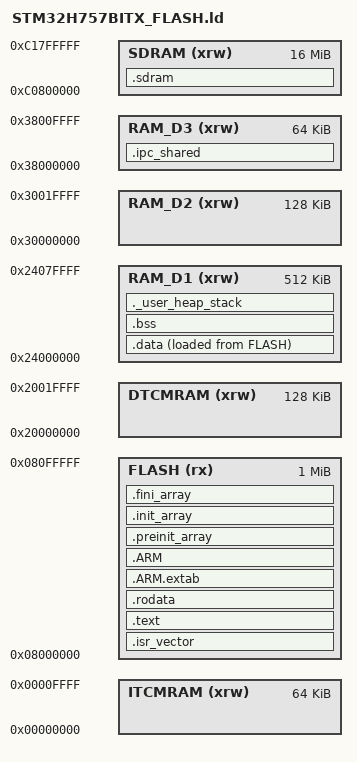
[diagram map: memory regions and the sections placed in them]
/*
******************************************************************************
**
**  File        : LinkerScript.ld
**
**  Author      : STM32CubeIDE
**
**  Abstract    : Linker script for STM32H7 series
**                      1024Kbytes FLASH
**                      800Kbytes RAM
**
**                Set heap size, stack size and stack location according
**                to application requirements.
**
**                Set memory bank area and size if external memory is used.
**
**  Target      : STMicroelectronics STM32
**
**  Distribution: The file is distributed as is without any warranty
**                of any kind.
**
*****************************************************************************
** @attention
**
** Copyright (c) 2024 STMicroelectronics.
** All rights reserved.
**
** This software is licensed under terms that can be found in the LICENSE file
** in the root directory of this software component.
** If no LICENSE file comes with this software, it is provided AS-IS.
**
*****************************************************************************
*/

/* Entry Point */
ENTRY(Reset_Handler)

/* Highest address of the user mode stack */
_estack = ORIGIN(RAM_D1) + LENGTH(RAM_D1); /* end of "RAM_D1" Ram type memory */

_Min_Heap_Size = 0x200; /* required amount of heap  */
_Min_Stack_Size = 0x400; /* required amount of stack */

/* Memories definition */
MEMORY
{
  RAM_D1 (xrw)   : ORIGIN = 0x24000000, LENGTH =  512K
  FLASH   (rx)   : ORIGIN = 0x08000000, LENGTH = 1024K    /* Memory is divided. Actual start is 0x08000000 and actual length is 2048K */
  DTCMRAM (xrw)  : ORIGIN = 0x20000000, LENGTH = 128K
  RAM_D2 (xrw)   : ORIGIN = 0x30000000, LENGTH = 128K  /* D2 SPLIT: CM7 = SRAM1 (128K). CM4 vlastni SRAM2+3 (160K @0x10020000, viz CM4 linker + NAVRH §11.5). Diagnosticky 'ram write/read' (0x30001000, ~78 KB) se vejde do SRAM1. CM7 do RAM_D2 nic nelinkuje. */
  RAM_D3 (xrw)   : ORIGIN = 0x38000000, LENGTH = 64K
  ITCMRAM (xrw)  : ORIGIN = 0x00000000, LENGTH = 64K
  /* Externi SDRAM scratch (FMC). 0xC0800000 = volne nad bignum regionem
   * (viz CLAUDE.md SDRAM mapa: R0 2MB @C0000000, R1 4MB @C0400000). Slouzi pro
   * .sdram sekci (libprim glow + screen caches). Mimo MPU R0/R1 -> default mapa
   * = Device pamet (pristupne, DMA2D-koherentni). */
  SDRAM (xrw)    : ORIGIN = 0xC0800000, LENGTH = 16M
}

/* Sections */
SECTIONS
{
  /* The startup code into "FLASH" Rom type memory */
  .isr_vector :
  {
    . = ALIGN(4);
    KEEP(*(.isr_vector)) /* Startup code */
    . = ALIGN(4);
  } >FLASH

  /* The program code and other data into "FLASH" Rom type memory */
  .text :
  {
    . = ALIGN(4);
    *(.text)           /* .text sections (code) */
    *(.text*)          /* .text* sections (code) */
    *(.glue_7)         /* glue arm to thumb code */
    *(.glue_7t)        /* glue thumb to arm code */
    *(.eh_frame)

    KEEP (*(.init))
    KEEP (*(.fini))

    . = ALIGN(4);
    _etext = .;        /* define a global symbols at end of code */
  } >FLASH

  /* Constant data into "FLASH" Rom type memory */
  .rodata :
  {
    . = ALIGN(4);
    *(.rodata)         /* .rodata sections (constants, strings, etc.) */
    *(.rodata*)        /* .rodata* sections (constants, strings, etc.) */
    . = ALIGN(4);
  } >FLASH

  .ARM.extab (READONLY) : /* The READONLY keyword is only supported in GCC11 and later, remove it if using GCC10 or earlier. */
  {
    . = ALIGN(4);
    *(.ARM.extab* .gnu.linkonce.armextab.*)
    . = ALIGN(4);
  } >FLASH
  .ARM (READONLY) : /* The READONLY keyword is only supported in GCC11 and later, remove it if using GCC10 or earlier. */
  {
    . = ALIGN(4);
    __exidx_start = .;
    *(.ARM.exidx*)
    __exidx_end = .;
    . = ALIGN(4);
  } >FLASH

  .preinit_array (READONLY) : /* The READONLY keyword is only supported in GCC11 and later, remove it if using GCC10 or earlier. */
  {
    . = ALIGN(4);
    PROVIDE_HIDDEN (__preinit_array_start = .);
    KEEP (*(.preinit_array*))
    PROVIDE_HIDDEN (__preinit_array_end = .);
    . = ALIGN(4);
  } >FLASH

  .init_array (READONLY) : /* The READONLY keyword is only supported in GCC11 and later, remove it if using GCC10 or earlier. */
  {
    . = ALIGN(4);
    PROVIDE_HIDDEN (__init_array_start = .);
    KEEP (*(SORT(.init_array.*)))
    KEEP (*(.init_array*))
    PROVIDE_HIDDEN (__init_array_end = .);
    . = ALIGN(4);
  } >FLASH

  .fini_array (READONLY) : /* The READONLY keyword is only supported in GCC11 and later, remove it if using GCC10 or earlier. */
  {
    . = ALIGN(4);
    PROVIDE_HIDDEN (__fini_array_start = .);
    KEEP (*(SORT(.fini_array.*)))
    KEEP (*(.fini_array*))
    PROVIDE_HIDDEN (__fini_array_end = .);
    . = ALIGN(4);
  } >FLASH

  /* Used by the startup to initialize data */
  _sidata = LOADADDR(.data);

  /* Initialized data sections into "RAM" Ram type memory */
  .data :
  {
    . = ALIGN(4);
    _sdata = .;        /* create a global symbol at data start */
    *(.data)           /* .data sections */
    *(.data*)          /* .data* sections */
    *(.RamFunc)        /* .RamFunc sections */
    *(.RamFunc*)       /* .RamFunc* sections */

    . = ALIGN(4);
    _edata = .;        /* define a global symbol at data end */
  } >RAM_D1 AT> FLASH

  /* Uninitialized data section into "RAM" Ram type memory */
  . = ALIGN(4);
  .bss :
  {
    /* This is used by the startup in order to initialize the .bss section */
    _sbss = .;         /* define a global symbol at bss start */
    __bss_start__ = _sbss;
    *(.bss)
    *(.bss*)
    *(COMMON)

    . = ALIGN(4);
    _ebss = .;         /* define a global symbol at bss end */
    __bss_end__ = _ebss;
  } >RAM_D1

  /* Externi SDRAM scratch (NOLOAD): libprim glow scratch + GPSDO screen caches.
   * Naplnuje se za behu, takze zadny load z FLASH. @0xC0800000 (viz MEMORY). */
  .sdram (NOLOAD) :
  {
    . = ALIGN(32);
    *(.sdram)
    *(.sdram*)
    . = ALIGN(32);
  } >SDRAM

  /* IPC sdilena pamet CM7<->CM4 (SRAM4 / domena D3, 0x38000000, 64 KB). NOLOAD
   * (plni se za behu, zadny load z FLASH). ⚠️ MUSI byt non-cacheable — zajistuje
   * MPU region 2 v main.c MPU_Config(); bez toho by CM7 cetl stara data z D-cache
   * a IPC by "skoro fungovalo" a padalo nahodne. Zatim jen REZERVACE celeho D3
   * regionu (nic jineho ho nepouziva); vlastni obsah (ipc_snapshot + cmd/resp
   * ringy) prijde s IPC vrstvou. Data se sem umisti: __attribute__((section(".ipc_shared"))). */
  .ipc_shared (NOLOAD) :
  {
    . = ALIGN(32);
    _sipc_shared = .;
    KEEP(*(.ipc_shared))
    KEEP(*(.ipc_shared*))
    . = ALIGN(32);
    _eipc_shared = .;
  } >RAM_D3

  /* User_heap_stack section, used to check that there is enough "RAM" Ram  type memory left */
  ._user_heap_stack :
  {
    . = ALIGN(8);
    PROVIDE ( end = . );
    PROVIDE ( _end = . );
    . = . + _Min_Heap_Size;
    . = . + _Min_Stack_Size;
    . = ALIGN(8);
  } >RAM_D1

  /* Remove information from the compiler libraries */
  /DISCARD/ :
  {
    libc.a ( * )
    libm.a ( * )
    libgcc.a ( * )
  }

  .ARM.attributes 0 : { *(.ARM.attributes) }
}
